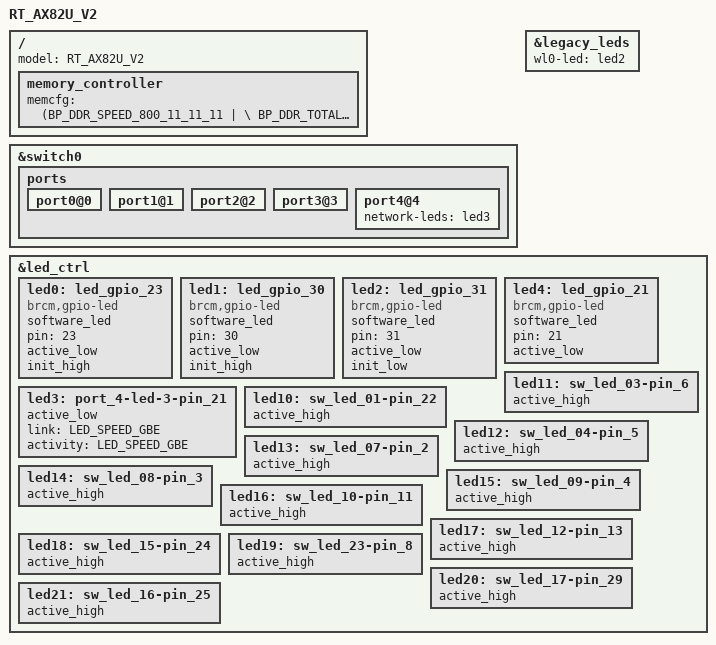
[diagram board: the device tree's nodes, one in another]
#include "63178.dtsi"

/ {
    model = "RT_AX82U_V2";

    memory_controller {
        memcfg = <(BP_DDR_SPEED_800_11_11_11 | \
                   BP_DDR_TOTAL_SIZE_512MB   | \
                   BP_DDR_DEVICE_WIDTH_16    | \
                   BP_DDR_TOTAL_WIDTH_16BIT  | \
                   BP_DDR_63178_DEFAULT)>;
    };
#if 0
	buttons {
		compatible = "brcm,buttons";
		reset_button {
			ext_irq = <&bca_extintr 0 BCA_GPIO_ACTIVE_LOW (BCA_EXTINTR_TYPE_LOW_LEVEL | BCA_EXTINTR_TYPE_SENSE_EDGE)>;
			press {
				print = "Button Press -- Hold for 5s to do restore to default";
			};
			hold {
				rst_to_dflt = <5>;
			};
			release {
				reset = <0>;
			};	
		};
		ses_button {
			ext_irq = <&bca_extintr 1 BCA_GPIO_ACTIVE_LOW (BCA_EXTINTR_TYPE_LOW_LEVEL | BCA_EXTINTR_TYPE_SENSE_EDGE)>;
			release {
				ses_short_period = <0>;
				ses_long_period = <3>;
			};
		};
	};
#endif
};

&switch0 {
	ports {
		port0@0 {
			status = "okay";
		};

		port1@1 {
			status = "okay";
		};

		port2@2 {
			status = "okay";
		};

		port3@3 {
			status = "okay";
		};

		port4@4 {
			status = "okay";
			network-leds = <&led3>;
		};
	};
};

&legacy_leds {
	wl0-led = <&led2>;
};

&led_ctrl {
	status = "okay";

	/* GPIO_23: POWER */
	led0:led_gpio_23 {
		compatible = "brcm,gpio-led";
		software_led;
		pin = <23>;
		active_low;
		init_high;
	};

	/* GPIO_30: WAN RED */
	led1:led_gpio_30 {
		compatible = "brcm,gpio-led";
		software_led;
		pin = <30>;
		active_low;
		init_high;
	};

	/* WLAN_2G_ACT */
	led2:led_gpio_31 {
		compatible = "brcm,gpio-led";
		software_led;
		pin = <31>;
		active_low;
		init_low;
	};

	/* WAN LED */
	led3: port_4-led-3-pin_21 {
		active_low;
		link = <LED_SPEED_GBE>;
		activity = <LED_SPEED_GBE>;
		status = "okay";
	};

	/* WAN LED GPIO */
	led4:led_gpio_21 {
		compatible = "brcm,gpio-led";
		software_led;
		pin = <21>;
		active_low;
	};

	/* LED Group1 Red */
	led10: sw_led_01-pin_22 {
		active_high;
		status = "okay";
	};

	/* LED Group1 Green */
	led11: sw_led_03-pin_6 {
		active_high;
		status = "okay";
	};

	/* LED Group1 Blue */
	led12: sw_led_04-pin_5 {
		active_high;
		status = "okay";
	};

	/* LED Group2 Red */
	led13: sw_led_07-pin_2 {
		active_high;
		status = "okay";
	};

	/* LED Group2 Green */
	led14: sw_led_08-pin_3 {
		active_high;
		status = "okay";
	};

	/* LED Group2 Blue */
	led15: sw_led_09-pin_4 {
		active_high;
		status = "okay";
	};

	/* LED Group3 Red */
	led16: sw_led_10-pin_11 {
		active_high;
		status = "okay";
	};

	/* LED Group3 Green */
	led17: sw_led_12-pin_13 {
		active_high;
		status = "okay";
	};

	/* LED Group3 Blue */
	led18: sw_led_15-pin_24 {
		active_high;
		status = "okay";
	};

	/* LED Group4 Red */
	led19: sw_led_23-pin_8 {
		active_high;
		status = "okay";
	};

	/* LED Group4 Green */
	led20: sw_led_17-pin_29 {
		active_high;
		status = "okay";
	};

	/* LED Group4 Blue */
	led21: sw_led_16-pin_25 {
		active_high;
		status = "okay";
	};
#if 0
	/* LED Group1 Red GPIO */
	led30:led_gpio_22 {
		compatible = "brcm,gpio-led";
		software_led;
		pin = <22>;
		active_high;
		init_low;
	};

	/* LED Group1 Green GPIO */
	led31:led_gpio_6 {
		compatible = "brcm,gpio-led";
		software_led;
		pin = <6>;
		active_high;
		init_low;
	};

	/* LED Group1 Blue GPIO */
	led32:led_gpio_5 {
		compatible = "brcm,gpio-led";
		software_led;
		pin = <5>;
		active_high;
		init_low;
	};

	/* LED Group2 Red GPIO */
	led33:led_gpio_2 {
		compatible = "brcm,gpio-led";
		software_led;
		pin = <2>;
		active_high;
		init_low;
	};

	/* LED Group2 Green GPIO */
	led34:led_gpio_3 {
		compatible = "brcm,gpio-led";
		software_led;
		pin = <3>;
		active_high;
		init_low;
	};

	/* LED Group2 Blue GPIO */
	led35:led_gpio_4 {
		compatible = "brcm,gpio-led";
		software_led;
		pin = <4>;
		active_high;
		init_low;
	};

	/* LED Group3 Red GPIO */
	led36:led_gpio_11 {
		compatible = "brcm,gpio-led";
		software_led;
		pin = <11>;
		active_high;
		init_low;
	};

	/* LED Group3 Green GPIO */
	led37:led_gpio_13 {
		compatible = "brcm,gpio-led";
		software_led;
		pin = <13>;
		active_high;
		init_low;
	};

	/* LED Group3 Blue GPIO */
	led38:led_gpio_24 {
		compatible = "brcm,gpio-led";
		software_led;
		pin = <24>;
		active_high;
		init_low;
	};

	/* LED Group4 Red GPIO */
	led39:led_gpio_8 {
		compatible = "brcm,gpio-led";
		software_led;
		pin = <8>;
		active_high;
		init_low;
	};

	/* LED Group4 Green GPIO */
	led40:led_gpio_29 {
		compatible = "brcm,gpio-led";
		software_led;
		pin = <29>;
		active_high;
		init_low;
	};

	/* LED Group4 Blue GPIO */
	led41:led_gpio_25 {
		compatible = "brcm,gpio-led";
		software_led;
		pin = <25>;
		active_high;
		init_low;
	};
#endif
};
